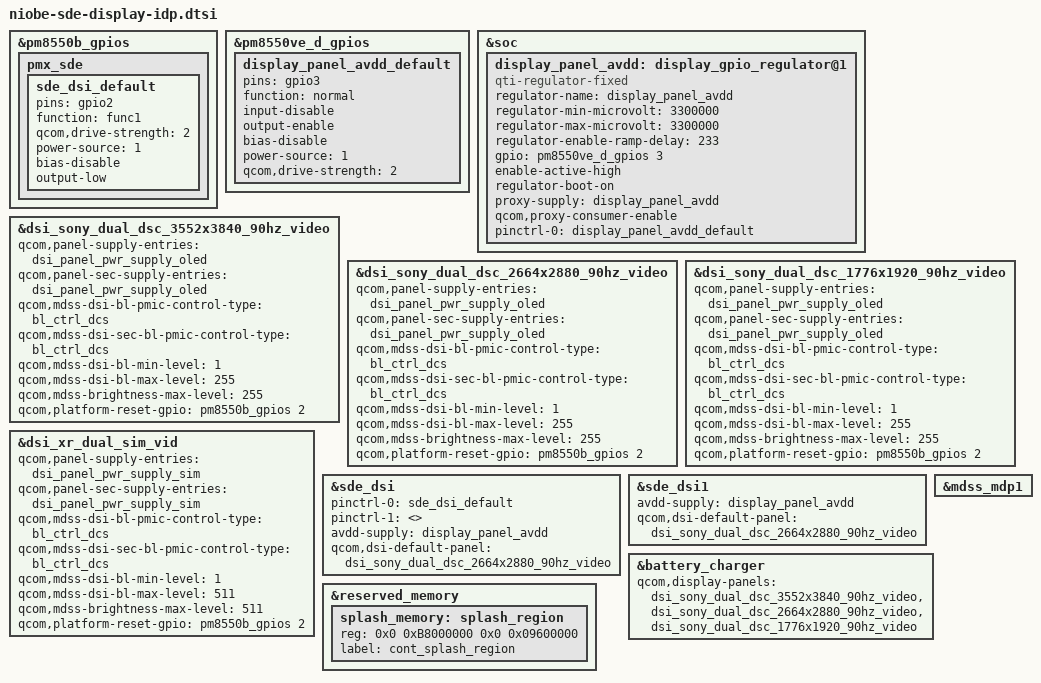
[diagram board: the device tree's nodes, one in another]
#include "niobe-sde-display.dtsi"

&pm8550b_gpios {
	pmx_sde: pmx_sde {
		sde_dsi_default: sde_dsi_default {
			pins = "gpio2";
			function = "func1";
			qcom,drive-strength = <2>;
			power-source = <1>;
			bias-disable;
			output-low;
		};
	};
};

&pm8550ve_d_gpios {
	display_panel_avdd_default: display_panel_avdd_default {
		pins = "gpio3";
		function = "normal";
		input-disable;
		output-enable;
		bias-disable;
		power-source = <1>;
		qcom,drive-strength = <2>;
	};
};

&soc {
	display_panel_avdd: display_gpio_regulator@1 {
		compatible = "qti-regulator-fixed";
		regulator-name = "display_panel_avdd";
		regulator-min-microvolt = <3300000>;
		regulator-max-microvolt = <3300000>;
		regulator-enable-ramp-delay = <233>;
		gpio = <&pm8550ve_d_gpios 3 0>;
		enable-active-high;
		regulator-boot-on;
		proxy-supply = <&display_panel_avdd>;
		qcom,proxy-consumer-enable;
		pinctrl-names = "default";
		pinctrl-0 = <&display_panel_avdd_default>;
	};
};

&dsi_sony_dual_dsc_3552x3840_90hz_video {
	qcom,panel-supply-entries = <&dsi_panel_pwr_supply_oled>;
	qcom,panel-sec-supply-entries = <&dsi_panel_pwr_supply_oled>;
	qcom,mdss-dsi-bl-pmic-control-type = "bl_ctrl_dcs";
	qcom,mdss-dsi-sec-bl-pmic-control-type = "bl_ctrl_dcs";
	qcom,mdss-dsi-bl-min-level = <1>;
	qcom,mdss-dsi-bl-max-level = <255>;
	qcom,mdss-brightness-max-level = <255>;
	qcom,platform-reset-gpio = <&pm8550b_gpios 2 0>;
};

&dsi_sony_dual_dsc_2664x2880_90hz_video {
	qcom,panel-supply-entries = <&dsi_panel_pwr_supply_oled>;
	qcom,panel-sec-supply-entries = <&dsi_panel_pwr_supply_oled>;
	qcom,mdss-dsi-bl-pmic-control-type = "bl_ctrl_dcs";
	qcom,mdss-dsi-sec-bl-pmic-control-type = "bl_ctrl_dcs";
	qcom,mdss-dsi-bl-min-level = <1>;
	qcom,mdss-dsi-bl-max-level = <255>;
	qcom,mdss-brightness-max-level = <255>;
	qcom,platform-reset-gpio = <&pm8550b_gpios 2 0>;
};

&dsi_sony_dual_dsc_1776x1920_90hz_video {
	qcom,panel-supply-entries = <&dsi_panel_pwr_supply_oled>;
	qcom,panel-sec-supply-entries = <&dsi_panel_pwr_supply_oled>;
	qcom,mdss-dsi-bl-pmic-control-type = "bl_ctrl_dcs";
	qcom,mdss-dsi-sec-bl-pmic-control-type = "bl_ctrl_dcs";
	qcom,mdss-dsi-bl-min-level = <1>;
	qcom,mdss-dsi-bl-max-level = <255>;
	qcom,mdss-brightness-max-level = <255>;
	qcom,platform-reset-gpio = <&pm8550b_gpios 2 0>;
};

&dsi_xr_dual_sim_vid {
	qcom,panel-supply-entries = <&dsi_panel_pwr_supply_sim>;
	qcom,panel-sec-supply-entries = <&dsi_panel_pwr_supply_sim>;
	qcom,mdss-dsi-bl-pmic-control-type = "bl_ctrl_dcs";
	qcom,mdss-dsi-sec-bl-pmic-control-type = "bl_ctrl_dcs";
	qcom,mdss-dsi-bl-min-level = <1>;
	qcom,mdss-dsi-bl-max-level = <511>;
	qcom,mdss-brightness-max-level = <511>;
	qcom,platform-reset-gpio = <&pm8550b_gpios 2 0>;
};

&sde_dsi {
	pinctrl-names = "panel_active", "panel_suspend";
	pinctrl-0 = <&sde_dsi_default>;
	pinctrl-1 = <>;
	avdd-supply = <&display_panel_avdd>;
	qcom,dsi-default-panel = <&dsi_sony_dual_dsc_2664x2880_90hz_video>;
};

&sde_dsi1 {
	avdd-supply = <&display_panel_avdd>;
	qcom,dsi-default-panel = <&dsi_sony_dual_dsc_2664x2880_90hz_video>;
};

&mdss_mdp1 {
	status = "ok";
};

&battery_charger {
	qcom,display-panels = <&dsi_sony_dual_dsc_3552x3840_90hz_video
				&dsi_sony_dual_dsc_2664x2880_90hz_video
				&dsi_sony_dual_dsc_1776x1920_90hz_video>;
};

&reserved_memory {
	splash_memory: splash_region {
		reg = <0x0 0xB8000000 0x0 0x09600000>;
		label = "cont_splash_region";
	};
};
